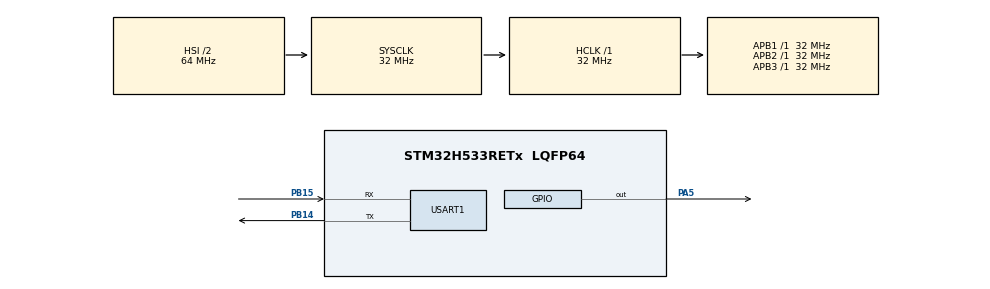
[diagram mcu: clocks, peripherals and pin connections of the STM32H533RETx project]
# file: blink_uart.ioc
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BOOTPATH.BootPathName=LEGACY
BOOTPATH.UserSelectedBootPath=LEGACY
CORTEX_M33_NS.Number-Cortex_Memory_Protection_Unit_Region0_OTP_RO_AREAS_Settings=MPU_REGION_NUMBER0
CORTEX_M33_NS.default_mode_Activation=1
CORTEX_M33_NS.userName=CORTEX_M33
Mcu.Family=STM32H5
Mcu.Name=STM32H533RETx
Mcu.Package=LQFP64
NUCLEO-H533RE.BUTTON=1
NUCLEO-H533RE.LD4=true
NVIC.EXTI13_IRQn=true\:0\:0\:false\:false\:true\:false\:true\:true
NVIC.PriorityGroup=NVIC_PRIORITYGROUP_4
PA13(JTMS/SWDIO).GPIO_Label=SWDIO
PA13(JTMS/SWDIO).Signal=DEBUG_JTMS-SWDIO
PA14(JTCK/SWCLK).GPIO_Label=SWCLK
PA14(JTCK/SWCLK).Signal=DEBUG_JTCK-SWCLK
PA15(JTDI).GPIO_Label=JTDI
PA15(JTDI).Signal=DEBUG_JTDI
PA2.Signal=USART2_TX
PA3.Signal=USART2_RX
PA5.Signal=GPIO_Output
PB14.Mode=Asynchronous
PB14.Signal=USART1_TX
PB15.Mode=Asynchronous
PB15.Signal=USART1_RX
PB3(JTDO/TRACESWO).GPIO_Label=SWO
PB3(JTDO/TRACESWO).Signal=DEBUG_JTDO-SWO
ProjectManager.HeapSize=0x200
ProjectManager.StackSize=0x400
ProjectManager.TargetToolchain=STM32CubeIDE
RCC.ADCFreq_Value=32000000
RCC.AHBFreq_Value=32000000
RCC.APB1Freq_Value=32000000
RCC.APB1TimFreq_Value=32000000
RCC.APB2Freq_Value=32000000
RCC.APB2TimFreq_Value=32000000
RCC.APB3Freq_Value=32000000
RCC.CSI_VALUE=4000000
RCC.CortexFreq_Value=32000000
RCC.EPOD_VALUE=4000000
RCC.HCLKFreq_Value=32000000
RCC.HSE_VALUE=25000000
RCC.HSI48_VALUE=48000000
RCC.HSI_VALUE=64000000
RCC.LSE_VALUE=32768
RCC.LSIRC_VALUE=32000
RCC.SYSCLKFreq_VALUE=32000000
RCC.USBFreq_Value=48000000
RCC.VCOOutputFreq_Value=516000000
USART1.VirtualMode-Asynchronous=VM_ASYNC
VP_BOOTPATH_VS_BOOTPATH.Mode=BP_Activate
VP_CORTEX_M33_NS_VS_Hclk.Mode=Hclk_Mode
VP_ICACHE_VS_ICACHE.Mode=DirectMappedCache
VP_MEMORYMAP_VS_MEMORYMAP.Mode=CurAppReg
VP_NUCLEO-H533RE_VS_BSP_COMMON.Mode=COMMON
VP_PWR_VS_LPOM.Mode=PowerOptimisation
VP_PWR_VS_SECSignals.Mode=Security/Privilege
board=NUCLEO-H533RE

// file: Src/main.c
/* USER CODE BEGIN Header */
/**
  ******************************************************************************
  * @file           : main.c
  * @brief          : Main program body
  ******************************************************************************
  * @attention
  *
  * Copyright (c) 2026 STMicroelectronics.
  * All rights reserved.
  *
  * This software is licensed under terms that can be found in the LICENSE file
  * in the root directory of this software component.
  * If no LICENSE file comes with this software, it is provided AS-IS.
  *
  ******************************************************************************
  */
/* USER CODE END Header */
#include "main.h"
#include <string.h>

UART_HandleTypeDef huart1;

/* USER CODE BEGIN PV */
static const char hello_msg[] = "HELLO\r\n";
/* USER CODE END PV */

void SystemClock_Config(void);
static void MPU_Config(void);
static void MX_GPIO_Init(void);
static void MX_ICACHE_Init(void);
static void MX_USART1_UART_Init(void);

int main(void)
{

  /* MCU Configuration--------------------------------------------------------*/

  /* MPU Configuration--------------------------------------------------------*/
  MPU_Config();

  /* Reset of all peripherals, Initializes the Flash interface and the Systick. */
  HAL_Init();

  /* Configure the system clock */
  SystemClock_Config();

  /* Initialize all configured peripherals */
  MX_GPIO_Init();
  MX_ICACHE_Init();
  MX_USART1_UART_Init();

  /* Initialize leds */
  BSP_LED_Init(LED_GREEN);

  /* Initialize USER push-button, will be used to trigger an interrupt each time it's pressed.*/
  BSP_PB_Init(BUTTON_USER, BUTTON_MODE_EXTI);

  /* Infinite loop */
  while (1)
  {
	  BSP_LED_Toggle(LED_GREEN);

	      HAL_UART_Transmit(&huart1,
	                        (uint8_t *)hello_msg,
	                        strlen(hello_msg),
	                        HAL_MAX_DELAY);
	      HAL_Delay(500);
  }
}

void SystemClock_Config(void)
{
  RCC_OscInitTypeDef RCC_OscInitStruct = {0};
  RCC_ClkInitTypeDef RCC_ClkInitStruct = {0};

  /** Configure the main internal regulator output voltage
  */
  __HAL_PWR_VOLTAGESCALING_CONFIG(PWR_REGULATOR_VOLTAGE_SCALE3);

  while(!__HAL_PWR_GET_FLAG(PWR_FLAG_VOSRDY)) {}

  /** Initializes the RCC Oscillators according to the specified parameters
  * in the RCC_OscInitTypeDef structure.
  */
  RCC_OscInitStruct.OscillatorType = RCC_OSCILLATORTYPE_HSI;
  RCC_OscInitStruct.HSIState = RCC_HSI_ON;
  RCC_OscInitStruct.HSIDiv = RCC_HSI_DIV2;
  RCC_OscInitStruct.HSICalibrationValue = RCC_HSICALIBRATION_DEFAULT;
  RCC_OscInitStruct.PLL.PLLState = RCC_PLL_NONE;
  if (HAL_RCC_OscConfig(&RCC_OscInitStruct) != HAL_OK)
  {
    Error_Handler();
  }

  /** Initializes the CPU, AHB and APB buses clocks
  */
  RCC_ClkInitStruct.ClockType = RCC_CLOCKTYPE_HCLK|RCC_CLOCKTYPE_SYSCLK
                              |RCC_CLOCKTYPE_PCLK1|RCC_CLOCKTYPE_PCLK2
                              |RCC_CLOCKTYPE_PCLK3;
  RCC_ClkInitStruct.SYSCLKSource = RCC_SYSCLKSOURCE_HSI;
  RCC_ClkInitStruct.AHBCLKDivider = RCC_SYSCLK_DIV1;
  RCC_ClkInitStruct.APB1CLKDivider = RCC_HCLK_DIV1;
  RCC_ClkInitStruct.APB2CLKDivider = RCC_HCLK_DIV1;
  RCC_ClkInitStruct.APB3CLKDivider = RCC_HCLK_DIV1;

  if (HAL_RCC_ClockConfig(&RCC_ClkInitStruct, FLASH_LATENCY_1) != HAL_OK)
  {
    Error_Handler();
  }

  /** Configure the programming delay
  */
  __HAL_FLASH_SET_PROGRAM_DELAY(FLASH_PROGRAMMING_DELAY_0);
}

static void MX_ICACHE_Init(void)
{

  /** Enable instruction cache in 1-way (direct mapped cache)
  */
  if (HAL_ICACHE_ConfigAssociativityMode(ICACHE_1WAY) != HAL_OK)
  {
    Error_Handler();
  }
  if (HAL_ICACHE_Enable() != HAL_OK)
  {
    Error_Handler();
  }

}

static void MX_USART1_UART_Init(void)
{

  huart1.Instance = USART1;
  huart1.Init.BaudRate = 115200;
  huart1.Init.WordLength = UART_WORDLENGTH_8B;
  huart1.Init.StopBits = UART_STOPBITS_1;
  huart1.Init.Parity = UART_PARITY_NONE;
  huart1.Init.Mode = UART_MODE_TX_RX;
  huart1.Init.HwFlowCtl = UART_HWCONTROL_NONE;
  huart1.Init.OverSampling = UART_OVERSAMPLING_16;
  huart1.Init.OneBitSampling = UART_ONE_BIT_SAMPLE_DISABLE;
  huart1.Init.ClockPrescaler = UART_PRESCALER_DIV1;
  huart1.AdvancedInit.AdvFeatureInit = UART_ADVFEATURE_NO_INIT;
  if (HAL_UART_Init(&huart1) != HAL_OK)
  {
    Error_Handler();
  }
  if (HAL_UARTEx_SetTxFifoThreshold(&huart1, UART_TXFIFO_THRESHOLD_1_8) != HAL_OK)
  {
    Error_Handler();
  }
  if (HAL_UARTEx_SetRxFifoThreshold(&huart1, UART_RXFIFO_THRESHOLD_1_8) != HAL_OK)
  {
    Error_Handler();
  }
  if (HAL_UARTEx_DisableFifoMode(&huart1) != HAL_OK)
  {
    Error_Handler();
  }

}

static void MX_GPIO_Init(void)
{
  GPIO_InitTypeDef GPIO_InitStruct = {0};

  /* GPIO Ports Clock Enable */
  __HAL_RCC_GPIOA_CLK_ENABLE();
  __HAL_RCC_GPIOB_CLK_ENABLE();

  /*Configure GPIO pins : PA2 PA3 */
  GPIO_InitStruct.Pin = GPIO_PIN_2|GPIO_PIN_3;
  GPIO_InitStruct.Mode = GPIO_MODE_AF_PP;
  GPIO_InitStruct.Pull = GPIO_NOPULL;
  GPIO_InitStruct.Speed = GPIO_SPEED_FREQ_LOW;
  GPIO_InitStruct.Alternate = GPIO_AF7_USART2;
  HAL_GPIO_Init(GPIOA, &GPIO_InitStruct);

}

 /* MPU Configuration */

void MPU_Config(void)
{
  MPU_Region_InitTypeDef MPU_InitStruct = {0};
  MPU_Attributes_InitTypeDef MPU_AttributesInit = {0};

  /* Disables the MPU */
  HAL_MPU_Disable();

  /** Initializes and configures the Region 0 and the memory to be protected
  */
  MPU_InitStruct.Enable = MPU_REGION_ENABLE;
  MPU_InitStruct.Number = MPU_REGION_NUMBER0;
  MPU_InitStruct.BaseAddress = 0x08FFF000;
  MPU_InitStruct.LimitAddress = 0x08FFFFFF;
  MPU_InitStruct.AttributesIndex = MPU_ATTRIBUTES_NUMBER0;
  MPU_InitStruct.AccessPermission = MPU_REGION_ALL_RO;
  MPU_InitStruct.DisableExec = MPU_INSTRUCTION_ACCESS_DISABLE;
  MPU_InitStruct.IsShareable = MPU_ACCESS_NOT_SHAREABLE;

  HAL_MPU_ConfigRegion(&MPU_InitStruct);

  /** Initializes and configures the Attribute 0 and the memory to be protected
  */
  MPU_AttributesInit.Number = MPU_ATTRIBUTES_NUMBER0;
  MPU_AttributesInit.Attributes = INNER_OUTER(MPU_NOT_CACHEABLE);

  HAL_MPU_ConfigMemoryAttributes(&MPU_AttributesInit);
  /* Enables the MPU */
  HAL_MPU_Enable(MPU_PRIVILEGED_DEFAULT);

}

void Error_Handler(void)
{
  __disable_irq();
  while (1)
  {
  }
}
